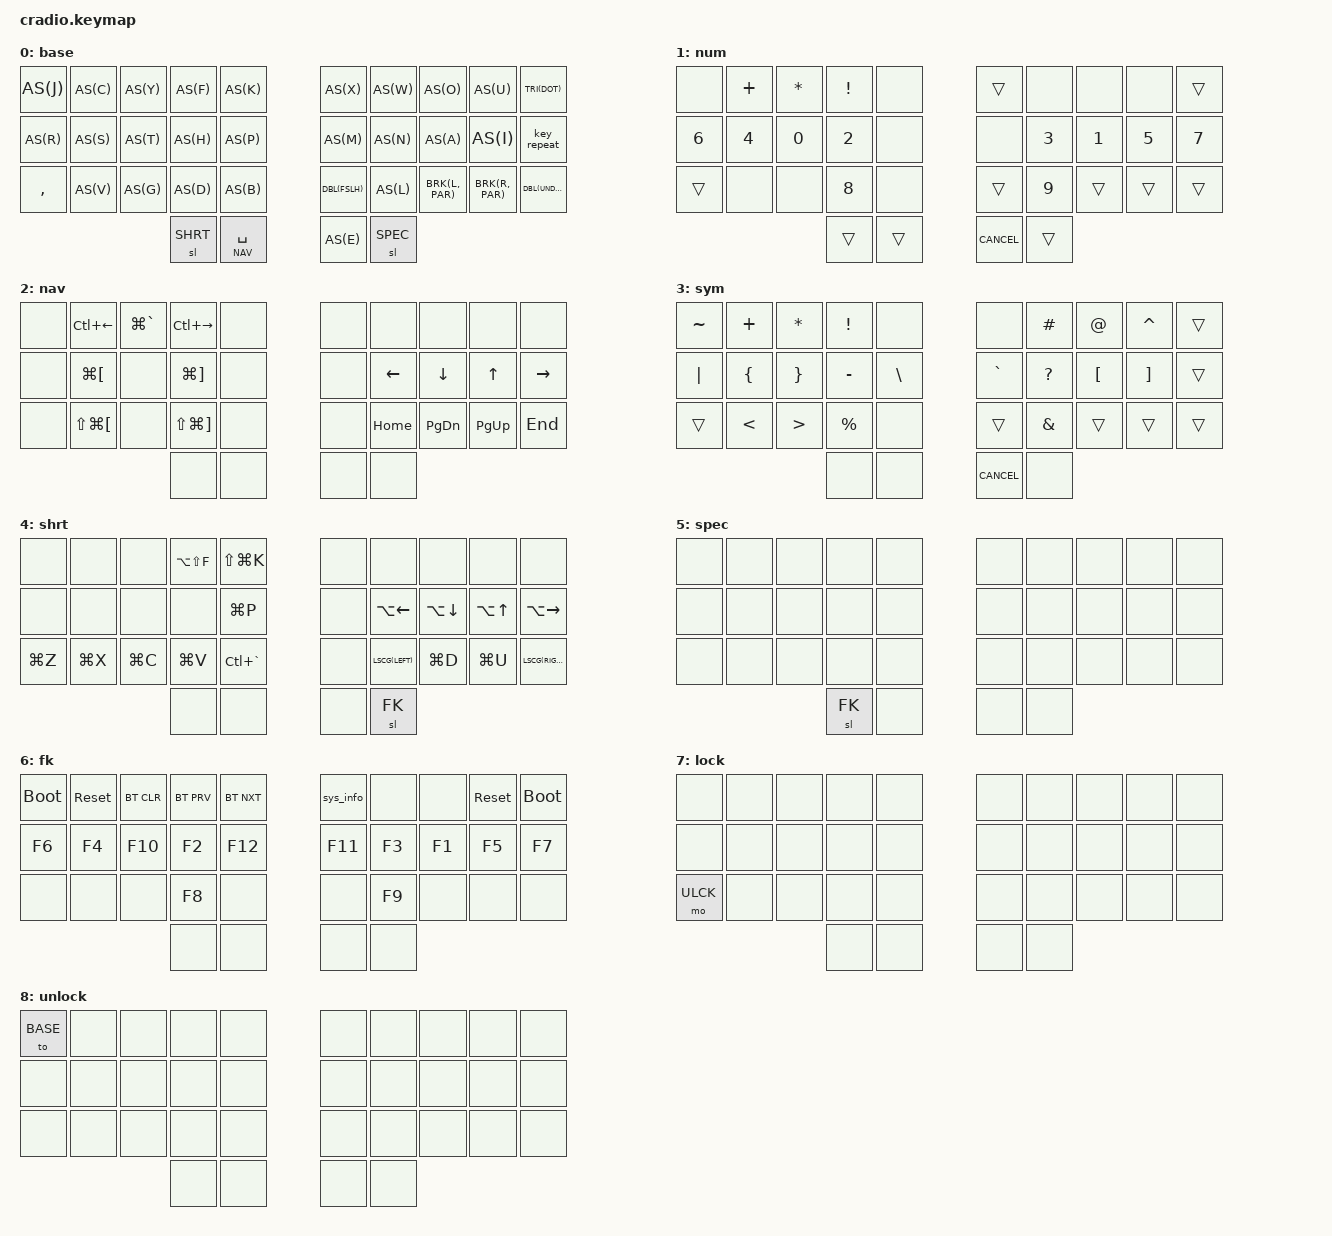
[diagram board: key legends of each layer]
// Copyright (c) 2022 The ZMK Contributors
// SPDX-License-Identifier: MIT

#include <behaviors.dtsi>
#include <dt-bindings/zmk/keys.h>
#include <dt-bindings/zmk/bt.h>

#include "keys.h"

// util
#define STR(x) #x

// layer
#define BASE 0
#define NUM 1
#define NAV 2
#define SYM 3
#define SHRT 4
#define SPEC 5
#define FK 6
#define GAME 7
#define LCK 8
#define ULCK 9

#define XXX         &none
#define ___         &trans

#define REPEAT      &key_repeat
#define CANCEL      &kp K_CANCEL

#define WSPC_PREV   &kp LC(LEFT)            // workspace next
#define WSPC_NEXT   &kp LC(RIGHT)           // workspace prev
#define WDW_NEXT    &kp LG(GRAVE)           // window next
#define TAB_NEXT    &kp LS(LG(RBKT))        // tab next
#define TAB_PREV    &kp LS(LG(LBKT))        // tab prev
#define BACK        &kp LG(LBKT)
#define FORWARD     &kp LG(RBKT)

#define LSCG(key)   &kp LS(LC(LG(key)))
#define NAV_SPC     &mt &mo NAV 

&num_word {
    layers = <NUM>;
    continue-list = <BSPC DOT COMMA PLUS MINUS STAR FSLH EQUAL X>;
};

// Autoshift
#define AS(keycode) &as LS(keycode) keycode
/ {
    behaviors {
        as: auto_shift {
            compatible = "zmk,behavior-hold-tap";
            label = "AUTO_SHIFT";
            #binding-cells = <2>;
            tapping_term_ms = <200>;
            quick_tap_ms = <125>;
            flavor = "tap-preferred";
            bindings = <&kp>, <&kp>;
        };
    };
};

#include "macros.dtsi"
#include "combos.dtsi"

/ {
    keymap {
        compatible = "zmk,keymap";
        
        base {
            bindings = <
                // ╭─────────────┬─────────────┬─────────────┬─────────────┬─────────────╮  ╭─────────────┬─────────────┬─────────────┬─────────────┬─────────────╮
                    AS(J)         AS(C)         AS(Y)         AS(F)         AS(K)            AS(X)         AS(W)         AS(O)         AS(U)         TRI(DOT)      
                // ├─────────────┼─────────────┼─────────────┼─────────────┼─────────────┤  ├─────────────┼─────────────┼─────────────┼─────────────┼─────────────┤
                    AS(R)         AS(S)         AS(T)         AS(H)         AS(P)            AS(M)         AS(N)         AS(A)         AS(I)         REPEAT  
                // ├─────────────┼─────────────┼─────────────┼─────────────┼─────────────┤  ├─────────────┼─────────────┼─────────────┼─────────────┼─────────────┤
                    &kp COMMA     AS(V)         AS(G)         AS(D)         AS(B)            DBL(FSLH)     AS(L)         BRK(L, PAR)   BRK(R, PAR)   DBL(UNDER)
                // ╰─────────────┴─────────────┴─────────────┼─────────────┼─────────────┤  ├─────────────┼─────────────┼─────────────┴─────────────┴─────────────╯
                                                              &sl SHRT      &lt NAV SPACE    AS(E)         &sl SPEC                                                  
                //                                           ╰─────────────┴─────────────╯  ╰─────────────┴─────────────╯                                          
            >;
        };

        num {
            bindings = <
                // ╭─────────────┬─────────────┬─────────────┬─────────────┬─────────────╮  ╭─────────────┬─────────────┬─────────────┬─────────────┬─────────────╮
                    XXX           &kp PLUS      &kp ASTRK     &kp EXCL      XXX              ___           XXX           XXX           XXX           ___
                // ├─────────────┼─────────────┼─────────────┼─────────────┼─────────────┤  ├─────────────┼─────────────┼─────────────┼─────────────┼─────────────┤
                    &kp N6        &kp N4        &kp N0        &kp N2        XXX              XXX           &kp N3        &kp N1        &kp N5        &kp N7
                // ├─────────────┼─────────────┼─────────────┼─────────────┼─────────────┤  ├─────────────┼─────────────┼─────────────┼─────────────┼─────────────┤
                    ___           XXX           XXX           &kp N8        XXX              ___           &kp N9        ___           ___           ___
                // ╰─────────────┴─────────────┴─────────────┼─────────────┼─────────────┤  ├─────────────┼─────────────┼─────────────┴─────────────┴─────────────╯
                                                              ___           ___              CANCEL        ___            
                //                                           ╰─────────────┴─────────────╯  ╰─────────────┴─────────────╯
            >;
        };

        nav {
            bindings = <
                // ╭─────────────┬─────────────┬─────────────┬─────────────┬─────────────╮  ╭─────────────┬─────────────┬─────────────┬─────────────┬─────────────╮
                    XXX           WSPC_PREV     WDW_NEXT      WSPC_NEXT     XXX              XXX           XXX           XXX           XXX           XXX
                // ├─────────────┼─────────────┼─────────────┼─────────────┼─────────────┤  ├─────────────┼─────────────┼─────────────┼─────────────┼─────────────┤
                    XXX           BACK          XXX           FORWARD       XXX              XXX           &kp LEFT      &kp DOWN      &kp UP        &kp RIGHT
                // ├─────────────┼─────────────┼─────────────┼─────────────┼─────────────┤  ├─────────────┼─────────────┼─────────────┼─────────────┼─────────────┤
                    XXX           TAB_PREV      XXX           TAB_NEXT      XXX              XXX           &kp HOME      &kp PG_DN     &kp PG_UP     &kp END
                // ╰─────────────┴─────────────┴─────────────┼─────────────┼─────────────┤  ├─────────────┼─────────────┼─────────────┴─────────────┴─────────────╯
                                                              XXX           XXX              XXX           XXX                                                  
                //                                           ╰─────────────┴─────────────╯  ╰─────────────┴─────────────╯                                          
            >;
        };

        sym {
            bindings = <
                // ╭─────────────┬─────────────┬─────────────┬─────────────┬─────────────╮  ╭─────────────┬─────────────┬─────────────┬─────────────┬─────────────╮
                    &kp TILDE     &kp PLUS      &kp ASTRK     &kp EXCL      XXX              XXX           &kp HASH      &kp AT        &kp CARET     ___
                // ├─────────────┼─────────────┼─────────────┼─────────────┼─────────────┤  ├─────────────┼─────────────┼─────────────┼─────────────┼─────────────┤
                    &kp PIPE      &kp LBRC      &kp RBRC      &kp MINUS     &kp BSLH         &kp GRAVE     &kp QMARK     &kp LBKT      &kp RBKT      ___
                // ├─────────────┼─────────────┼─────────────┼─────────────┼─────────────┤  ├─────────────┼─────────────┼─────────────┼─────────────┼─────────────┤
                    ___           &kp LT        &kp GT        &kp PRCNT     XXX              ___           &kp AMPS      ___           ___           ___
                // ╰─────────────┴─────────────┴─────────────┼─────────────┼─────────────┤  ├─────────────┼─────────────┼─────────────┴─────────────┴─────────────╯
                                                              XXX           XXX              CANCEL        XXX                                                  
                //                                           ╰─────────────┴─────────────╯  ╰─────────────┴─────────────╯                                          
            >;
        };

        shrt {
            bindings = <
                // ╭─────────────┬─────────────┬─────────────┬─────────────┬─────────────╮  ╭─────────────┬─────────────┬─────────────┬─────────────┬─────────────╮
                    XXX           XXX           XXX           &kp LA(LS(F)) &kp LS(LG(K))    XXX           XXX           XXX           XXX           XXX
                // ├─────────────┼─────────────┼─────────────┼─────────────┼─────────────┤  ├─────────────┼─────────────┼─────────────┼─────────────┼─────────────┤
                    XXX           XXX           XXX           XXX           &kp LG(P)        XXX           &kp LA(LEFT)  &kp LA(DOWN)  &kp LA(UP)    &kp LA(RIGHT)
                // ├─────────────┼─────────────┼─────────────┼─────────────┼─────────────┤  ├─────────────┼─────────────┼─────────────┼─────────────┼─────────────┤
                    &kp LG(Z)     &kp LG(X)     &kp LG(C)     &kp LG(V)     &kp LC(GRAVE)    XXX           LSCG(LEFT)    &kp LG(D)     &kp LG(U)     LSCG(RIGHT)
                // ╰─────────────┴─────────────┴─────────────┼─────────────┼─────────────┤  ├─────────────┼─────────────┼─────────────┴─────────────┴─────────────╯
                                                              XXX           XXX              XXX           &sl FK                                                  
                //                                           ╰─────────────┴─────────────╯  ╰─────────────┴─────────────╯                                          
            >;
        };

        spec {
            bindings = <
                // ╭─────────────┬─────────────┬─────────────┬─────────────┬─────────────╮  ╭─────────────┬─────────────┬─────────────┬─────────────┬─────────────╮
                    XXX           XXX           XXX           XXX           XXX              XXX           XXX           XXX           XXX           XXX
                // ├─────────────┼─────────────┼─────────────┼─────────────┼─────────────┤  ├─────────────┼─────────────┼─────────────┼─────────────┼─────────────┤
                    XXX           XXX           XXX           XXX           XXX              XXX           XXX           XXX           XXX           XXX
                // ├─────────────┼─────────────┼─────────────┼─────────────┼─────────────┤  ├─────────────┼─────────────┼─────────────┼─────────────┼─────────────┤
                    XXX           XXX           XXX           XXX           XXX              XXX           XXX           XXX           XXX           XXX
                // ╰─────────────┴─────────────┴─────────────┼─────────────┼─────────────┤  ├─────────────┼─────────────┼─────────────┴─────────────┴─────────────╯
                                                              &sl FK        XXX              XXX           XXX                                                 
                //                                           ╰─────────────┴─────────────╯  ╰─────────────┴─────────────╯                                          
            >;
        };

        fk {
            bindings = <
                // ╭─────────────┬─────────────┬─────────────┬─────────────┬─────────────╮  ╭─────────────┬─────────────┬─────────────┬─────────────┬─────────────╮
                    &bootloader   &sys_reset    &bt BT_CLR    &bt BT_PRV    &bt BT_NXT       &sys_info     XXX           XXX           &sys_reset    &bootloader
                // ├─────────────┼─────────────┼─────────────┼─────────────┼─────────────┤  ├─────────────┼─────────────┼─────────────┼─────────────┼─────────────┤
                    &kp F6        &kp F4        &kp F10       &kp F2        &kp F12          &kp F11       &kp F3        &kp F1        &kp F5        &kp F7
                // ├─────────────┼─────────────┼─────────────┼─────────────┼─────────────┤  ├─────────────┼─────────────┼─────────────┼─────────────┼─────────────┤
                    XXX           XXX           XXX           &kp F8        XXX              XXX           &kp F9        XXX           XXX           XXX
                // ╰─────────────┴─────────────┴─────────────┼─────────────┼─────────────┤  ├─────────────┼─────────────┼─────────────┴─────────────┴─────────────╯
                                                              XXX           XXX              XXX           XXX                                                  
                //                                           ╰─────────────┴─────────────╯  ╰─────────────┴─────────────╯                                          
            >;
        };

        lock {
            bindings = <
                // ╭─────────────┬─────────────┬─────────────┬─────────────┬─────────────╮  ╭─────────────┬─────────────┬─────────────┬─────────────┬─────────────╮
                    XXX           XXX           XXX           XXX           XXX              XXX           XXX           XXX           XXX           XXX
                // ├─────────────┼─────────────┼─────────────┼─────────────┼─────────────┤  ├─────────────┼─────────────┼─────────────┼─────────────┼─────────────┤
                    XXX           XXX           XXX           XXX           XXX              XXX           XXX           XXX           XXX           XXX
                // ├─────────────┼─────────────┼─────────────┼─────────────┼─────────────┤  ├─────────────┼─────────────┼─────────────┼─────────────┼─────────────┤
                    &mo ULCK      XXX           XXX           XXX           XXX              XXX           XXX           XXX           XXX           XXX
                // ╰─────────────┴─────────────┴─────────────┼─────────────┼─────────────┤  ├─────────────┼─────────────┼─────────────┴─────────────┴─────────────╯
                                                              XXX           XXX              XXX           XXX                                                  
                //                                           ╰─────────────┴─────────────╯  ╰─────────────┴─────────────╯                                          
            >;
        };

        unlock {
            bindings = <
                // ╭─────────────┬─────────────┬─────────────┬─────────────┬─────────────╮  ╭─────────────┬─────────────┬─────────────┬─────────────┬─────────────╮
                    &to BASE      XXX           XXX           XXX           XXX              XXX           XXX           XXX           XXX           XXX
                // ├─────────────┼─────────────┼─────────────┼─────────────┼─────────────┤  ├─────────────┼─────────────┼─────────────┼─────────────┼─────────────┤
                    XXX           XXX           XXX           XXX           XXX              XXX           XXX           XXX           XXX           XXX
                // ├─────────────┼─────────────┼─────────────┼─────────────┼─────────────┤  ├─────────────┼─────────────┼─────────────┼─────────────┼─────────────┤
                    XXX           XXX           XXX           XXX           XXX              XXX           XXX           XXX           XXX           XXX
                // ╰─────────────┴─────────────┴─────────────┼─────────────┼─────────────┤  ├─────────────┼─────────────┼─────────────┴─────────────┴─────────────╯
                                                              XXX           XXX              XXX           XXX                                                  
                //                                           ╰─────────────┴─────────────╯  ╰─────────────┴─────────────╯                                          
            >;
        };
    };
};
